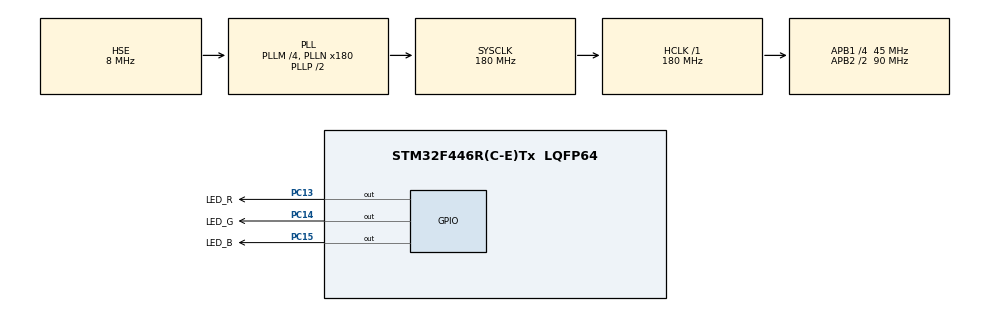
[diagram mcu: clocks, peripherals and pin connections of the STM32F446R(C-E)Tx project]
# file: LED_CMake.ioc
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Mcu.Family=STM32F4
Mcu.Name=STM32F446R(C-E)Tx
Mcu.Package=LQFP64
NVIC.PriorityGroup=NVIC_PRIORITYGROUP_4
PA13.Mode=Serial_Wire
PA13.Signal=SYS_JTMS-SWDIO
PA14.Mode=Serial_Wire
PA14.Signal=SYS_JTCK-SWCLK
PC13.GPIO_Label=LED_R
PC13.GPIO_ModeDefaultOutputPP=GPIO_MODE_OUTPUT_OD
PC13.GPIO_PuPd=GPIO_NOPULL
PC13.PinState=GPIO_PIN_SET
PC13.Signal=GPIO_Output
PC14-OSC32_IN.GPIO_Label=LED_G
PC14-OSC32_IN.GPIO_ModeDefaultOutputPP=GPIO_MODE_OUTPUT_OD
PC14-OSC32_IN.GPIO_PuPd=GPIO_NOPULL
PC14-OSC32_IN.PinState=GPIO_PIN_SET
PC14-OSC32_IN.Signal=GPIO_Output
PC15-OSC32_OUT.GPIO_Label=LED_B
PC15-OSC32_OUT.GPIO_ModeDefaultOutputPP=GPIO_MODE_OUTPUT_OD
PC15-OSC32_OUT.GPIO_PuPd=GPIO_NOPULL
PC15-OSC32_OUT.PinState=GPIO_PIN_SET
PC15-OSC32_OUT.Signal=GPIO_Output
PH0-OSC_IN.Mode=HSE-External-Clock-Source
PH0-OSC_IN.Signal=RCC_OSC_IN
PH1-OSC_OUT.Mode=HSE-External-Clock-Source
PH1-OSC_OUT.Signal=RCC_OSC_OUT
ProjectManager.HeapSize=0x200
ProjectManager.StackSize=0x400
ProjectManager.TargetToolchain=CMake
RCC.AHBFreq_Value=180000000
RCC.APB1CLKDivider=RCC_HCLK_DIV4
RCC.APB1Freq_Value=45000000
RCC.APB1TimFreq_Value=90000000
RCC.APB2CLKDivider=RCC_HCLK_DIV2
RCC.APB2Freq_Value=90000000
RCC.APB2TimFreq_Value=180000000
RCC.CortexFreq_Value=180000000
RCC.HCLKFreq_Value=180000000
RCC.HSE_VALUE=8000000
RCC.PLLM=4
RCC.PLLN=180
RCC.PLLSourceVirtual=RCC_PLLSOURCE_HSE
RCC.SYSCLKFreq_VALUE=180000000
RCC.SYSCLKSource=RCC_SYSCLKSOURCE_PLLCLK
RCC.USBFreq_Value=180000000
RCC.VCOOutputFreq_Value=360000000
board=custom

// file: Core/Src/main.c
/* USER CODE BEGIN Header */
/**
 ******************************************************************************
 * @file           : main.c
 * @brief          : Main program body
 ******************************************************************************
 * @attention
 *
 * Copyright (c) 2024 STMicroelectronics.
 * All rights reserved.
 *
 * This software is licensed under terms that can be found in the LICENSE file
 * in the root directory of this software component.
 * If no LICENSE file comes with this software, it is provided AS-IS.
 *
 ******************************************************************************
 */
/* USER CODE END Header */
#include "main.h"
#include "gpio.h"

/* USER CODE BEGIN Includes */

#include "flash.h"

/* USER CODE END Includes */

void SystemClock_Config(void);

int main(void) {

  /* MCU Configuration--------------------------------------------------------*/

  /* Reset of all peripherals, Initializes the Flash interface and the Systick.
   */
  HAL_Init();

  /* Configure the system clock */
  SystemClock_Config();

  /* Initialize all configured peripherals */
  MX_GPIO_Init();

  /* Infinite loop */
  /* USER CODE BEGIN WHILE */
  while (1) {
    led_flash(LED_R_GPIO_Port, LED_R_Pin, 1000);
    led_flash(LED_G_GPIO_Port, LED_G_Pin, 1000);
    led_flash(LED_B_GPIO_Port, LED_B_Pin, 1000);

    // led_flash(LED_R_GPIO_Port, LED_R_Pin);
    // led_flash(LED_G_GPIO_Port, LED_G_Pin);
    // led_flash(LED_B_GPIO_Port, LED_B_Pin);
    /* USER CODE END WHILE */

  }
}

void SystemClock_Config(void) {
  RCC_OscInitTypeDef RCC_OscInitStruct = {0};
  RCC_ClkInitTypeDef RCC_ClkInitStruct = {0};

  /** Configure the main internal regulator output voltage
   */
  __HAL_RCC_PWR_CLK_ENABLE();
  __HAL_PWR_VOLTAGESCALING_CONFIG(PWR_REGULATOR_VOLTAGE_SCALE1);

  /** Initializes the RCC Oscillators according to the specified parameters
   * in the RCC_OscInitTypeDef structure.
   */
  RCC_OscInitStruct.OscillatorType = RCC_OSCILLATORTYPE_HSE;
  RCC_OscInitStruct.HSEState = RCC_HSE_BYPASS;
  RCC_OscInitStruct.PLL.PLLState = RCC_PLL_ON;
  RCC_OscInitStruct.PLL.PLLSource = RCC_PLLSOURCE_HSE;
  RCC_OscInitStruct.PLL.PLLM = 4;
  RCC_OscInitStruct.PLL.PLLN = 180;
  RCC_OscInitStruct.PLL.PLLP = RCC_PLLP_DIV2;
  RCC_OscInitStruct.PLL.PLLQ = 2;
  RCC_OscInitStruct.PLL.PLLR = 2;
  if (HAL_RCC_OscConfig(&RCC_OscInitStruct) != HAL_OK) {
    Error_Handler();
  }

  /** Activate the Over-Drive mode
   */
  if (HAL_PWREx_EnableOverDrive() != HAL_OK) {
    Error_Handler();
  }

  /** Initializes the CPU, AHB and APB buses clocks
   */
  RCC_ClkInitStruct.ClockType = RCC_CLOCKTYPE_HCLK | RCC_CLOCKTYPE_SYSCLK |
                                RCC_CLOCKTYPE_PCLK1 | RCC_CLOCKTYPE_PCLK2;
  RCC_ClkInitStruct.SYSCLKSource = RCC_SYSCLKSOURCE_PLLCLK;
  RCC_ClkInitStruct.AHBCLKDivider = RCC_SYSCLK_DIV1;
  RCC_ClkInitStruct.APB1CLKDivider = RCC_HCLK_DIV4;
  RCC_ClkInitStruct.APB2CLKDivider = RCC_HCLK_DIV2;

  if (HAL_RCC_ClockConfig(&RCC_ClkInitStruct, FLASH_LATENCY_5) != HAL_OK) {
    Error_Handler();
  }
}

void Error_Handler(void) {
  __disable_irq();
  while (1) {
  }
}

#ifdef USE_FULL_ASSERT
/**
 * @brief  Reports the name of the source file and the source line number
 *         where the assert_param error has occurred.
 * @param  file: pointer to the source file name
 * @param  line: assert_param error line source number
 * @retval None
 */
void assert_failed(uint8_t *file, uint32_t line) {
  /* USER CODE BEGIN 6 */
  /* User can add his own implementation to report the file name and line
     number, ex: printf("Wrong parameters value: file %s on line %d\r\n", file,
     line) */
  /* USER CODE END 6 */
}
#endif /* USE_FULL_ASSERT */
